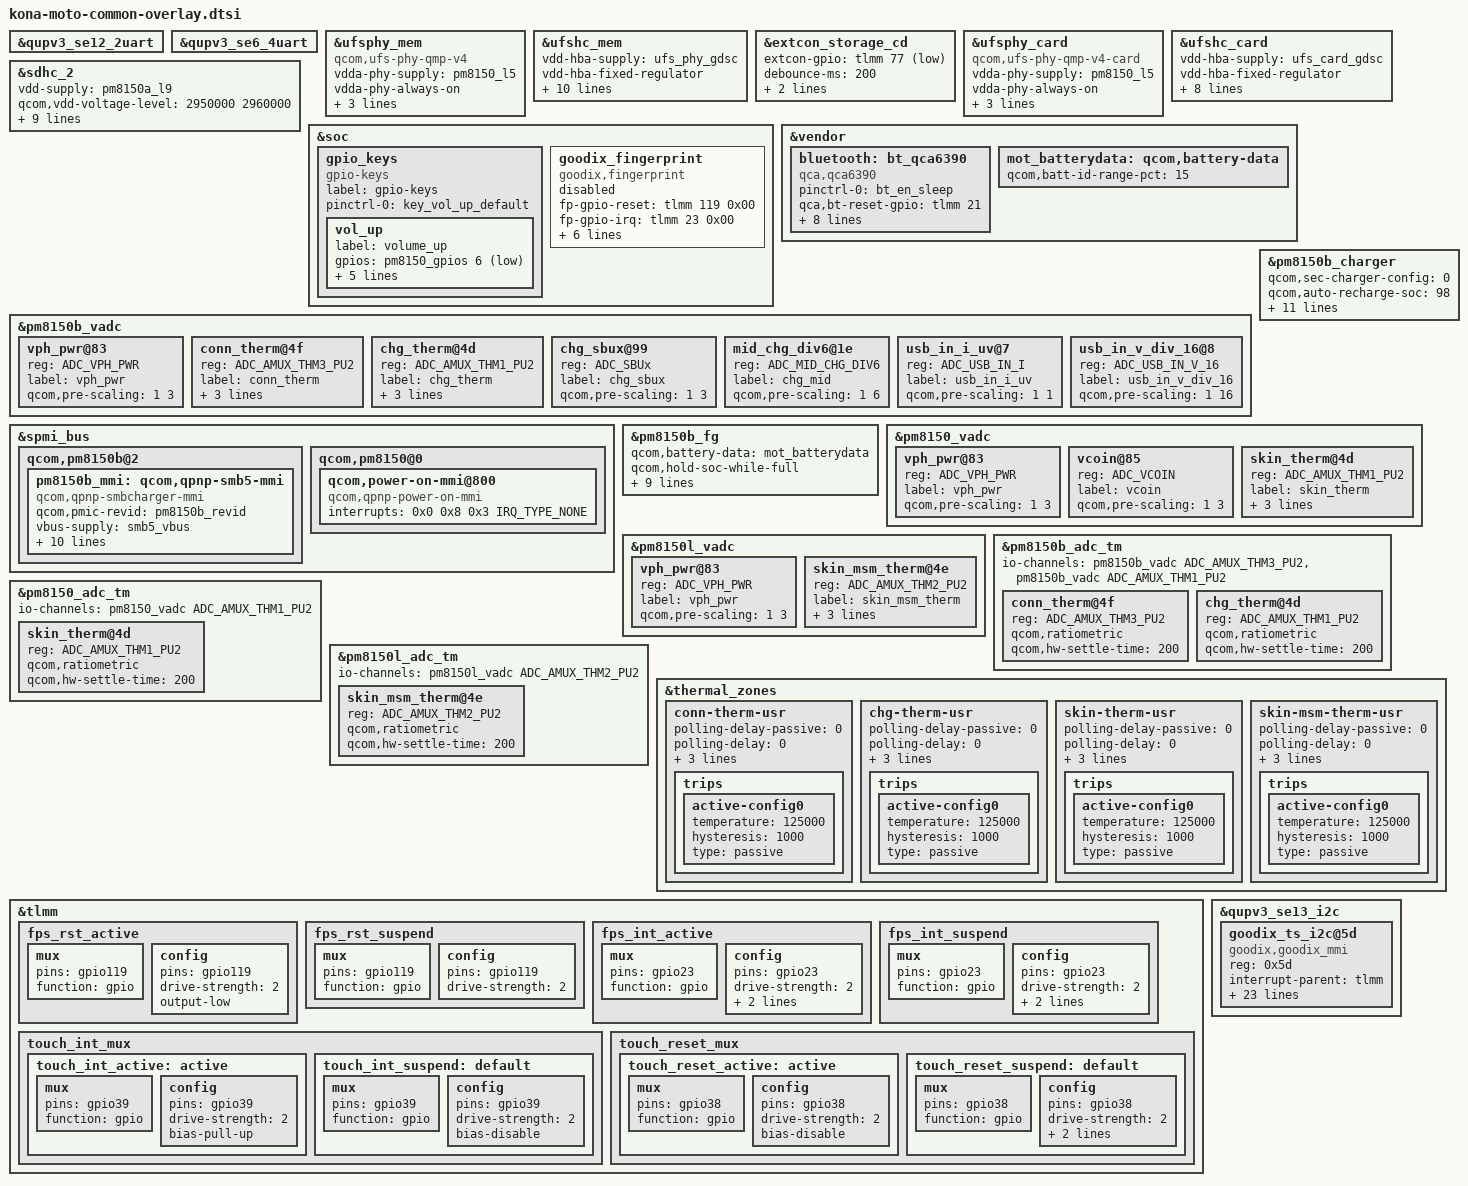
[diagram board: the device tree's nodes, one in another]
#include <dt-bindings/gpio/gpio.h>
#include <dt-bindings/input/input.h>

#include "kona-mot-burton-display.dtsi"
#include "kona-pmic-overlay.dtsi"
#include "kona-thermal-overlay.dtsi"

&qupv3_se12_2uart {
	status = "ok";
};

&qupv3_se6_4uart {
	status = "ok";
};

&ufsphy_mem {
	compatible = "qcom,ufs-phy-qmp-v4";

	vdda-phy-supply = <&pm8150_l5>;
	vdda-phy-always-on;
	vdda-pll-supply = <&pm8150_l9>;
	vdda-phy-max-microamp = <89900>;
	vdda-pll-max-microamp = <18800>;

	status = "ok";
};

&ufshc_mem {
	vdd-hba-supply = <&ufs_phy_gdsc>;
	vdd-hba-fixed-regulator;
	vcc-supply = <&pm8150_l17>;
	vcc-voltage-level = <2504000 2950000>;
	vcc-low-voltage-sup;
	vccq-supply = <&pm8150_l6>;
	vccq2-supply = <&pm8150_s4>;
	vcc-max-microamp = <800000>;
	vccq-max-microamp = <800000>;
	vccq2-max-microamp = <800000>;

	qcom,vddp-ref-clk-supply = <&pm8150_l6>;
	qcom,vddp-ref-clk-max-microamp = <100>;

	status = "ok";
};

&extcon_storage_cd {
	extcon-gpio = <&tlmm 77 GPIO_ACTIVE_LOW>;
	debounce-ms = <200>;
	irq-flags = <IRQ_TYPE_EDGE_BOTH>;

	pinctrl-names = "default";
	pinctrl-0 = <&storage_cd>;

	status = "ok";
};

&ufsphy_card {
	compatible = "qcom,ufs-phy-qmp-v4-card";

	vdda-phy-supply = <&pm8150_l5>; /* 0.88v */
	vdda-phy-always-on;
	vdda-pll-supply = <&pm8150_l9>; /* 1.2v */
	vdda-phy-max-microamp = <87100>;
	vdda-pll-max-microamp = <18300>;

	status = "ok";
};

&ufshc_card {
	vdd-hba-supply = <&ufs_card_gdsc>;
	vdd-hba-fixed-regulator;
	vcc-supply = <&pm8150a_l9>;
	vcc-voltage-level = <2950000 2960000>;
	vccq2-supply = <&pm8150_s4>;
	vcc-max-microamp = <500000>;
	vccq2-max-microamp = <400000>;

	qcom,vddp-ref-clk-supply = <&pm8150_l6>;
	qcom,vddp-ref-clk-max-microamp = <100>;

	extcon = <&extcon_storage_cd>;

	status = "ok";
};

&sdhc_2 {
	vdd-supply = <&pm8150a_l9>;
	qcom,vdd-voltage-level = <2950000 2960000>;
	qcom,vdd-current-level = <200 800000>;

	vdd-io-supply = <&pm8150a_l6>;
	qcom,vdd-io-voltage-level = <1808000 2960000>;
	qcom,vdd-io-current-level = <200 22000>;

	pinctrl-names = "active", "sleep";
	pinctrl-0 = <&sdc2_clk_on  &sdc2_cmd_on &sdc2_data_on>;
	pinctrl-1 = <&sdc2_clk_off &sdc2_cmd_off &sdc2_data_off>;

	extcon = <&extcon_storage_cd>;

	status = "ok";
};

&soc {
	gpio_keys {
		compatible = "gpio-keys";
		label = "gpio-keys";

		pinctrl-names = "default";
		pinctrl-0 = <&key_vol_up_default>;

		vol_up {
			label = "volume_up";
			gpios = <&pm8150_gpios 6 GPIO_ACTIVE_LOW>;
			linux,input-type = <1>;
			linux,code = <KEY_VOLUMEUP>;
			gpio-key,wakeup;
			debounce-interval = <15>;
			linux,can-disable;
		};
	};
};

&vendor {
	bluetooth: bt_qca6390 {
		compatible = "qca,qca6390";
		pinctrl-names = "default";
		pinctrl-0 = <&bt_en_sleep>;
		qca,bt-reset-gpio = <&tlmm 21 0>; /* BT_EN */
		qca,bt-vdd-aon-supply = <&pm8150_s6>;
		qca,bt-vdd-dig-supply = <&pm8009_s2>;
		qca,bt-vdd-rfa1-supply = <&pm8150_s5>;
		qca,bt-vdd-rfa2-supply = <&pm8150a_s8>;

		qca,bt-vdd-aon-voltage-level = <950000 950000>;
		qca,bt-vdd-dig-voltage-level = <950000 952000>;
		qca,bt-vdd-rfa1-voltage-level = <1900000 1900000>;
		qca,bt-vdd-rfa2-voltage-level = <1350000 1350000>;
	};

	mot_batterydata: qcom,battery-data {
		qcom,batt-id-range-pct = <15>;
		#include "fg-gen4-batterydata-alium-3600mah.dtsi"
		#include "fg-gen4-batterydata-ascent-3450mah.dtsi"
	};
};

&pm8150b_vadc {
	#address-cells = <1>;
	#size-cells = <0>;

	vph_pwr@83 {
		reg = <ADC_VPH_PWR>;
		label = "vph_pwr";
		qcom,pre-scaling = <1 3>;
	};

	conn_therm@4f {
		reg = <ADC_AMUX_THM3_PU2>;
		label = "conn_therm";
		qcom,ratiometric;
		qcom,hw-settle-time = <200>;
		qcom,pre-scaling = <1 1>;
	};

	chg_therm@4d {
		reg = <ADC_AMUX_THM1_PU2>;
		label = "chg_therm";
		qcom,ratiometric;
		qcom,hw-settle-time = <200>;
		qcom,pre-scaling = <1 1>;
	};

	chg_sbux@99 {
		reg = <ADC_SBUx>;
		label = "chg_sbux";
		qcom,pre-scaling = <1 3>;
	};

	mid_chg_div6@1e {
		reg = <ADC_MID_CHG_DIV6>;
		label = "chg_mid";
		qcom,pre-scaling = <1 6>;
	};

	usb_in_i_uv@7 {
		reg = <ADC_USB_IN_I>;
		label = "usb_in_i_uv";
		qcom,pre-scaling = <1 1>;
	};

	usb_in_v_div_16@8 {
		reg = <ADC_USB_IN_V_16>;
		label = "usb_in_v_div_16";
		qcom,pre-scaling = <1 16>;
	};
};

&pm8150b_charger {
	status = "ok";
	qcom,sec-charger-config = <0>;
	qcom,auto-recharge-soc = <98>;
	io-channels = <&pm8150b_vadc ADC_MID_CHG_DIV6>,
		      <&pm8150b_vadc ADC_USB_IN_I>,
		      <&pm8150b_vadc ADC_SBUx>,
		      <&pm8150b_vadc ADC_VPH_PWR>,
		      <&pm8150b_vadc ADC_CHG_TEMP>;
	io-channel-names = "mid_voltage",
			   "usb_in_current",
			   "sbux_res",
			   "vph_voltage",
			   "chg_temp";
	qcom,battery-data = <&mot_batterydata>;
	qcom,step-charging-enable;
	qcom,sw-jeita-enable;
	qcom,wd-bark-time-secs = <16>;
	qcom,suspend-input-on-debug-batt;
	qcom,fcc-stepping-enable;
};

&spmi_bus {
	qcom,pm8150b@2 {
		pm8150b_mmi: qcom,qpnp-smb5-mmi {
			compatible = "qcom,qpnp-smbcharger-mmi";
			qcom,pmic-revid = <&pm8150b_revid>;
			vbus-supply = <&smb5_vbus>;
			status = "ok";
			qcom,enable-charging-limit;
			qcom,enable-factory-poweroff;
			qcom,upper-limit-capacity = <75>;
			qcom,lower-limit-capacity = <60>;
			qcom,mmi-temp-zones = <0 4200 400 0>,
						<10 4200 1000 400>,
						<15 0 1000 1000>,
						<45 4200 2000 1400>,
						<60 4200 1000 0>;
			qcom,iterm-ma = <97>;
			qcom,vfloat-comp-uv = <20000>;
			qcom,dc-icl-ma = <500>;
		};
	};

	qcom,pm8150@0 {
		qcom,power-on-mmi@800 {
			compatible = "qcom,qpnp-power-on-mmi";
			interrupts = <0x0 0x8 0x3 IRQ_TYPE_NONE>;
			interrupt-names = "kpdpwr-bark";
		};
	};
};

&pm8150b_fg {
	status = "ok";
	qcom,battery-data = <&mot_batterydata>;
	qcom,hold-soc-while-full;
	qcom,linearize-soc;
	qcom,five-pin-battery;
	qcom,cl-wt-enable;
	/* ESR fast calibration */
	qcom,fg-esr-timer-chg-fast = <0 7>;
	qcom,fg-esr-timer-dischg-fast = <0 7>;
	qcom,fg-esr-timer-chg-slow = <0 96>;
	qcom,fg-esr-timer-dischg-slow = <0 96>;
	qcom,fg-esr-cal-soc-thresh = <26 230>;
	qcom,fg-esr-cal-temp-thresh = <10 40>;
};

&pm8150_vadc {
	#address-cells = <1>;
	#size-cells = <0>;

	vph_pwr@83 {
		reg = <ADC_VPH_PWR>;
		label = "vph_pwr";
		qcom,pre-scaling = <1 3>;
	};

	vcoin@85 {
		reg = <ADC_VCOIN>;
		label = "vcoin";
		qcom,pre-scaling = <1 3>;
	};

	skin_therm@4d {
		reg = <ADC_AMUX_THM1_PU2>;
		label = "skin_therm";
		qcom,ratiometric;
		qcom,hw-settle-time = <200>;
		qcom,pre-scaling = <1 1>;
	};
};

&pm8150l_vadc {
	#address-cells = <1>;
	#size-cells = <0>;

	vph_pwr@83 {
		reg = <ADC_VPH_PWR>;
		label = "vph_pwr";
		qcom,pre-scaling = <1 3>;
	};

	skin_msm_therm@4e {
		reg = <ADC_AMUX_THM2_PU2>;
		label = "skin_msm_therm";
		qcom,ratiometric;
		qcom,hw-settle-time = <200>;
		qcom,pre-scaling = <1 1>;
	};
};

&pm8150b_adc_tm {
	#address-cells = <1>;
	#size-cells = <0>;

	io-channels = <&pm8150b_vadc ADC_AMUX_THM3_PU2>,
        <&pm8150b_vadc ADC_AMUX_THM1_PU2>;

	conn_therm@4f {
		reg = <ADC_AMUX_THM3_PU2>;
		qcom,ratiometric;
		qcom,hw-settle-time = <200>;
	};

	chg_therm@4d {
		reg = <ADC_AMUX_THM1_PU2>;
		qcom,ratiometric;
		qcom,hw-settle-time = <200>;
	};
};

&pm8150_adc_tm {
	#address-cells = <1>;
	#size-cells = <0>;

	io-channels = <&pm8150_vadc ADC_AMUX_THM1_PU2>;

	skin_therm@4d {
		reg = <ADC_AMUX_THM1_PU2>;
		qcom,ratiometric;
		qcom,hw-settle-time = <200>;
	};
};

&pm8150l_adc_tm {
	#address-cells = <1>;
	#size-cells = <0>;

    io-channels = <&pm8150l_vadc ADC_AMUX_THM2_PU2>;

	skin_msm_therm@4e {
		reg = <ADC_AMUX_THM2_PU2>;
		qcom,ratiometric;
		qcom,hw-settle-time = <200>;
	};
};

&thermal_zones {
	conn-therm-usr {
		polling-delay-passive = <0>;
		polling-delay = <0>;
		thermal-governor = "user_space";
		thermal-sensors = <&pm8150b_adc_tm ADC_AMUX_THM3_PU2>;
		trips {
			active-config0 {
				temperature = <125000>;
				hysteresis = <1000>;
				type = "passive";
			};
		};
	};

	chg-therm-usr {
		polling-delay-passive = <0>;
		polling-delay = <0>;
		thermal-governor = "user_space";
		thermal-sensors = <&pm8150b_adc_tm ADC_AMUX_THM1_PU2>;
		trips {
			active-config0 {
				temperature = <125000>;
				hysteresis = <1000>;
				type = "passive";
			};
		};
	};

	skin-therm-usr {
		polling-delay-passive = <0>;
		polling-delay = <0>;
		thermal-governor = "user_space";
		thermal-sensors = <&pm8150_adc_tm ADC_AMUX_THM1_PU2>;
		trips {
			active-config0 {
				temperature = <125000>;
				hysteresis = <1000>;
				type = "passive";
			};
		};
	};

	skin-msm-therm-usr {
		polling-delay-passive = <0>;
		polling-delay = <0>;
		thermal-governor = "user_space";
		thermal-sensors = <&pm8150l_adc_tm ADC_AMUX_THM2_PU2>;
		trips {
			active-config0 {
				temperature = <125000>;
				hysteresis = <1000>;
				type = "passive";
			};
		};
	};
};

&tlmm{
	fps_rst_active: fps_rst_active {
		mux {
			pins = "gpio119";
			function = "gpio";
		};
		config {
			pins = "gpio119";
			drive-strength = <2>; /* 2 MA */
			output-low;
		};
	};

	fps_rst_suspend: fps_rst_suspend {
		mux {
			pins = "gpio119";
			function = "gpio";
		};
		config {
			pins = "gpio119";
			drive-strength = <2>; /* 2 MA */
		};
	};

	fps_int_active: fps_int_active {
		mux {
			pins = "gpio23";
			function = "gpio";
		};
		config {
			pins = "gpio23";
			drive-strength = <2>; /* 2 MA */
			bias-disable;
			input-enable;
		};
	};

	fps_int_suspend: fps_int_suspend {
		mux {
			pins = "gpio23";
			function = "gpio";
		};
		config {
			pins = "gpio23";
			drive-strength = <2>; /* 2 MA */
			bias-disable;
			input-enable;
		};
	};

	touch_int_mux {
		touch_int_active: active {
			mux {
				pins = "gpio39";
				function = "gpio";
			};
			config {
				pins = "gpio39";
				drive-strength = <2>;
				bias-pull-up;
			};
		};

		touch_int_suspend: default {
			mux {
				pins = "gpio39";
				function = "gpio";
			};
			config {
				pins = "gpio39";
				drive-strength = <2>;
				bias-disable;
			};
		};
	};

	touch_reset_mux {
		touch_reset_active: active {
			mux {
				pins = "gpio38";
				function = "gpio";
			};
			config {
				pins = "gpio38";
				drive-strength = <2>;
				bias-disable;
			};
		};

		touch_reset_suspend: default {
			mux {
				pins = "gpio38";
				function = "gpio";
			};
			config {
				pins = "gpio38";
				drive-strength = <2>;
				bias-pull-down;
				output-low;
			};
		};
	};
};

&soc {
	goodix_fingerprint{
		status = "disabled";
		compatible = "goodix,fingerprint";
		fp-gpio-reset = <&tlmm 119 0x00>;
		fp-gpio-irq = <&tlmm 23 0x00>;
		fp-gpio-ven = <&tlmm 120 0x00>;
		interrupt-parent = <&tlmm>;
		interrupts = <23 0>;
		interrupt-controller;
		pinctrl-names = "default", "suspend";
		pinctrl-0 = <&fps_rst_active &fps_int_active>;
		pinctrl-1 = <&fps_rst_suspend &fps_int_suspend>;
	};
};

&qupv3_se13_i2c {
	status = "okay";

	goodix_ts_i2c@5d {
		status = "ok";
		compatible = "goodix,goodix_mmi";
		reg = <0x5d>;
		interrupt-parent = <&tlmm>;
		interrupts = <39 0>;
		pinctrl-names = "pmx_ts_active","pmx_ts_suspend";
		pinctrl-0 = <&touch_int_active &touch_reset_active>;
		pinctrl-1 = <&touch_int_suspend &touch_reset_suspend>;
		/*goodix,reg-en-gpio = <&tlmm 120 0x0>;*/
		vtouch-supply = <&pm8150_l13>;
		/*iovtouch-supply = <&pm8150_s4>;*/
		goodix,reset-gpio = <&tlmm 38 0x0>;
		goodix,irq-gpio = <&tlmm 39 0x2002>;
		goodix,irq-flags = <0x2002>; /* 1:trigger rising, 2:trigger falling;*/
		goodix,control-dsi = <0>;
		goodix,panel-max-id = <10>;
		goodix,panel-max-x = <1080>;
		goodix,panel-max-y = <2340>;
		goodix,panel-max-w = <256>;
		goodix,panel-max-p = <4096>;
		goodix,power-on-delay-us = <300000>; /*300ms*/
		goodix,power-off-delay-us = <5000>;
		/*goodix,swap-axis;*/
		goodix,x2x;
		goodix,y2y;
		goodix,pen-enable;
		goodix,usb_charger;
		goodix,key-of-pen = <331 332>;/*BTN_STYLUS, BTN_STYLUS2*/
		goodix,debug-reg-ver = <1>;
	};
};
